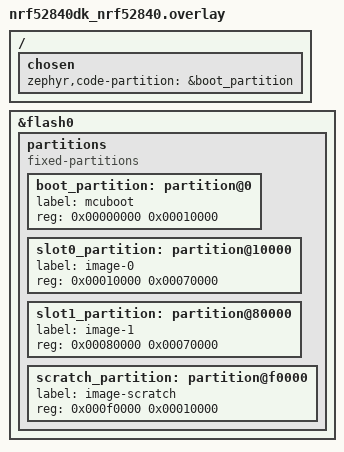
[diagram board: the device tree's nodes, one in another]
/*
 * MCUboot shares the application's fixed partition layout. Delete the
 * bootloader's default partition nodes first, then recreate them.
 */
/delete-node/ &boot_partition;
/delete-node/ &slot0_partition;
/delete-node/ &slot1_partition;

/ {
	chosen {
		zephyr,code-partition = &boot_partition;
	};
};

&flash0 {
	partitions {
		compatible = "fixed-partitions";
		#address-cells = <1>;
		#size-cells = <1>;

		boot_partition: partition@0 {
			label = "mcuboot";
			reg = <0x00000000 0x00010000>;
		};
		slot0_partition: partition@10000 {
			label = "image-0";
			reg = <0x00010000 0x00070000>;
		};
		slot1_partition: partition@80000 {
			label = "image-1";
			reg = <0x00080000 0x00070000>;
		};
		scratch_partition: partition@f0000 {
			label = "image-scratch";
			reg = <0x000f0000 0x00010000>;
		};
	};
};
